AUTOSAR XML (schema 4-2-2)
package /STELLANTIS/EPT/ASWCs
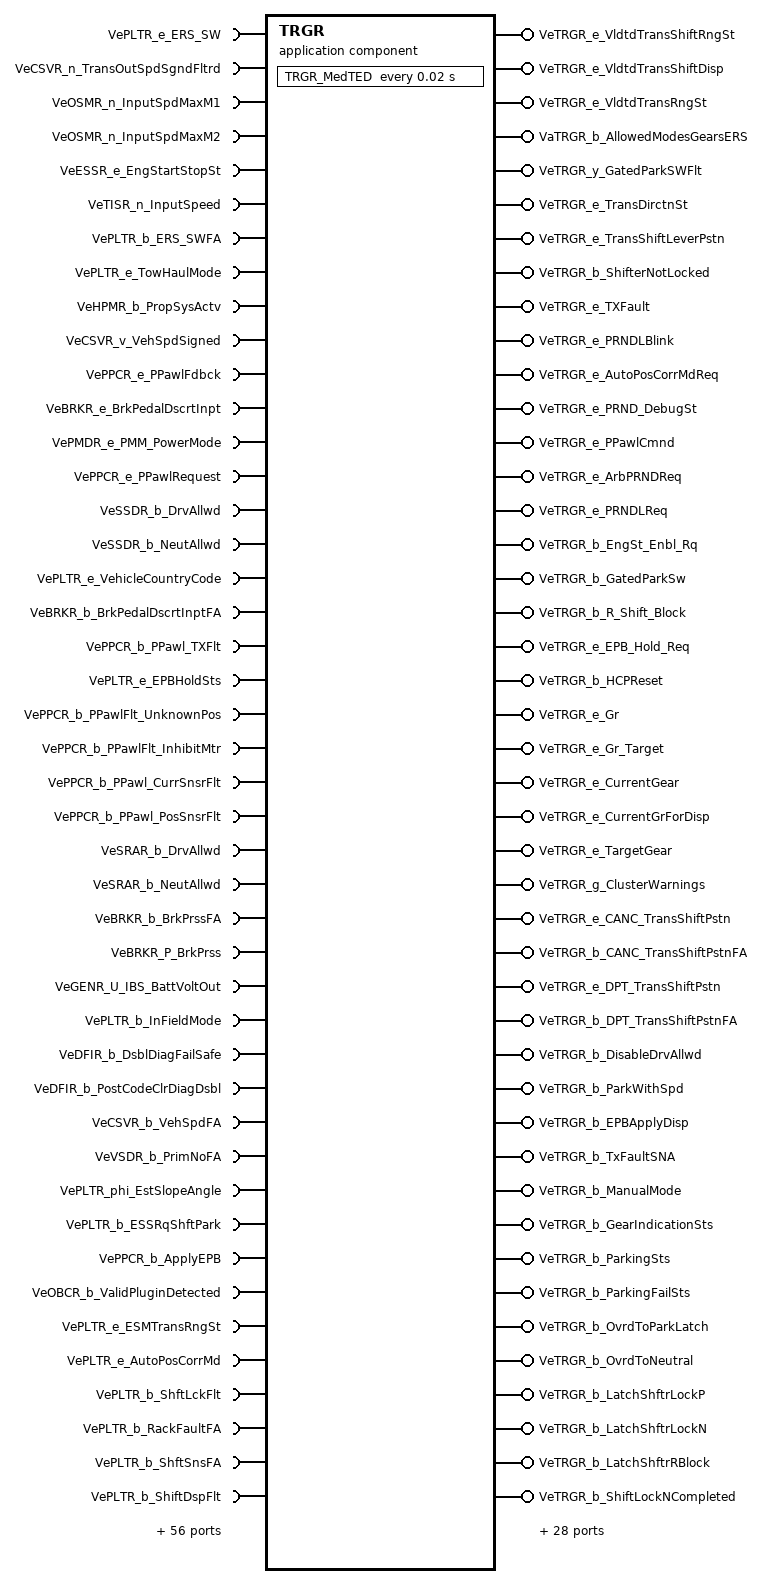
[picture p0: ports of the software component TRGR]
  application sw component type TRGR
    97 x require port:
      VePLTR_e_ERS_SW: variation-point={short-label=vpVePLTR_e_ERS_SW, sw-syscond=1}, nonqueued-receiver-com-spec{data-element=Value, init-value=CeTRGR_e_ERSBttn_NotActvtd}, required-interface=VePLTR_e_ERS_SW
      VeCSVR_n_TransOutSpdSgndFltrd: nonqueued-receiver-com-spec{data-element=Value, init-value=0}, required-interface=VeCSVR_n_TransOutSpdSgndFltrd
      VeOSMR_n_InputSpdMaxM1: variation-point={short-label=vpVeOSMR_n_InputSpdMaxM1, sw-syscond=1}, nonqueued-receiver-com-spec{data-element=Value, init-value=0}, required-interface=VeOSMR_n_InputSpdMaxM1
      VeOSMR_n_InputSpdMaxM2: variation-point={short-label=vpVeOSMR_n_InputSpdMaxM2, sw-syscond=1}, nonqueued-receiver-com-spec{data-element=Value, init-value=0}, required-interface=VeOSMR_n_InputSpdMaxM2
      VeESSR_e_EngStartStopSt: variation-point={short-label=vpVeESSR_e_EngStartStopSt, sw-syscond=1}, nonqueued-receiver-com-spec{data-element=Value, init-value=CeESSR_e_EngOff}, required-interface=VeESSR_e_EngStartStopSt
      VeTISR_n_InputSpeed: variation-point={short-label=vpVeTISR_n_InputSpeed, sw-syscond=1}, nonqueued-receiver-com-spec{data-element=Value, init-value=0}, required-interface=VeTISR_n_InputSpeed
      VePLTR_b_ERS_SWFA: variation-point={short-label=vpVePLTR_b_ERS_SWFA, sw-syscond=1}, nonqueued-receiver-com-spec{data-element=Value, init-value=0}, required-interface=VePLTR_b_ERS_SWFA
      VePLTR_e_TowHaulMode: variation-point={short-label=vpVePLTR_e_TowHaulMode, sw-syscond=1}, nonqueued-receiver-com-spec{data-element=Value, init-value=CePLTR_e_Towing_MD_RQ_OFF}, required-interface=VePLTR_e_TowHaulMode
      VeHPMR_b_PropSysActv: variation-point={short-label=vpVeHPMR_b_PropSysActv, sw-syscond=1}, nonqueued-receiver-com-spec{data-element=Value, init-value=0}, required-interface=VeHPMR_b_PropSysActv
      VeCSVR_v_VehSpdSigned: nonqueued-receiver-com-spec{data-element=Value, init-value=0}, required-interface=VeCSVR_v_VehSpdSigned
      VePPCR_e_PPawlFdbck: variation-point={short-label=vpVePPCR_e_PPawlFdbck, sw-syscond=1}, nonqueued-receiver-com-spec{data-element=Value, init-value=CePPCR_e_PPAWL_UNKNOWN_Position}, required-interface=VePPCR_e_PPawlFdbck
      VeBRKR_e_BrkPedalDscrtInpt: nonqueued-receiver-com-spec{data-element=Value, init-value=CeBRKR_e_BrkNotApplied}, required-interface=VeBRKR_e_BrkPedalDscrtInpt
      VePMDR_e_PMM_PowerMode: variation-point={short-label=vpVePMDR_e_PMM_PowerMode, sw-syscond=1}, nonqueued-receiver-com-spec{data-element=Value, init-value=CePMDR_e_PowerMode_Off}, required-interface=VePMDR_e_PMM_PowerMode
      VePPCR_e_PPawlRequest: variation-point={short-label=vpVePPCR_e_PPawlRequest, sw-syscond=1}, nonqueued-receiver-com-spec{data-element=Value, init-value=CePPCR_e_PPAWL_UNKNOWN_Request}, required-interface=VePPCR_e_PPawlRequest
      VeSSDR_b_DrvAllwd: nonqueued-receiver-com-spec{data-element=Value, init-value=0}, required-interface=VeSSDR_b_DrvAllwd
      VeSSDR_b_NeutAllwd: nonqueued-receiver-com-spec{data-element=Value, init-value=0}, required-interface=VeSSDR_b_NeutAllwd
      VePLTR_e_VehicleCountryCode: variation-point={short-label=vpVePLTR_e_VehicleCountryCode, sw-syscond=1}, nonqueued-receiver-com-spec{data-element=Value, init-value=CePLTR_e_VCC_OTHERS}, required-interface=VePLTR_e_VehicleCountryCode
      VeBRKR_b_BrkPedalDscrtInptFA: nonqueued-receiver-com-spec{data-element=Value, init-value=0}, required-interface=VeBRKR_b_BrkPedalDscrtInptFA
      VePPCR_b_PPawl_TXFlt: variation-point={short-label=vpVePPCR_b_PPawl_TXFlt, sw-syscond=1}, nonqueued-receiver-com-spec{data-element=Value, init-value=0}, required-interface=VePPCR_b_PPawl_TXFlt
      VePLTR_e_EPBHoldSts: nonqueued-receiver-com-spec{data-element=Value, init-value=CePLTR_e_EPBHoldSts_REL}, required-interface=VePLTR_e_EPBHoldSts
      VePPCR_b_PPawlFlt_UnknownPos: variation-point={short-label=vpVePPCR_b_PPawlFlt_UnknownPos, sw-syscond=1}, nonqueued-receiver-com-spec{data-element=Value, init-value=0}, required-interface=VePPCR_b_PPawlFlt_UnknownPos
      VePPCR_b_PPawlFlt_InhibitMtr: variation-point={short-label=vpVePPCR_b_PPawlFlt_InhibitMtr, sw-syscond=1}, nonqueued-receiver-com-spec{data-element=Value, init-value=0}, required-interface=VePPCR_b_PPawlFlt_InhibitMtr
      VePPCR_b_PPawl_CurrSnsrFlt: variation-point={short-label=vpVePPCR_b_PPawl_CurrSnsrFlt, sw-syscond=1}, nonqueued-receiver-com-spec{data-element=Value, init-value=0}, required-interface=VePPCR_b_PPawl_CurrSnsrFlt
      VePPCR_b_PPawl_PosSnsrFlt: variation-point={short-label=vpVePPCR_b_PPawl_PosSnsrFlt, sw-syscond=1}, nonqueued-receiver-com-spec{data-element=Value, init-value=0}, required-interface=VePPCR_b_PPawl_PosSnsrFlt
      VeSRAR_b_DrvAllwd: nonqueued-receiver-com-spec{data-element=Value, init-value=0}, required-interface=VeSRAR_b_DrvAllwd
      VeSRAR_b_NeutAllwd: nonqueued-receiver-com-spec{data-element=Value, init-value=0}, required-interface=VeSRAR_b_NeutAllwd
      VeBRKR_b_BrkPrssFA: nonqueued-receiver-com-spec{data-element=Value, init-value=0}, required-interface=VeBRKR_b_BrkPrssFA
      VeBRKR_P_BrkPrss: nonqueued-receiver-com-spec{data-element=Value, init-value=0}, required-interface=VeBRKR_P_BrkPrss
      VeGENR_U_IBS_BattVoltOut: variation-point={short-label=vpVeGENR_U_IBS_BattVoltOut, sw-syscond=1}, nonqueued-receiver-com-spec{data-element=Value, init-value=0}, required-interface=VeGENR_U_IBS_BattVoltOut
      VePLTR_b_InFieldMode: variation-point={short-label=vpVePLTR_b_InFieldMode, sw-syscond=1}, nonqueued-receiver-com-spec{data-element=Value, init-value=0}, required-interface=VePLTR_b_InFieldMode
      VeDFIR_b_DsblDiagFailSafe: variation-point={short-label=vpVeDFIR_b_DsblDiagFailSafe, sw-syscond=1}, nonqueued-receiver-com-spec{data-element=Value, init-value=0}, required-interface=VeDFIR_b_DsblDiagFailSafe
      VeDFIR_b_PostCodeClrDiagDsbl: variation-point={short-label=vpVeDFIR_b_PostCodeClrDiagDsbl, sw-syscond=1}, nonqueued-receiver-com-spec{data-element=Value, init-value=0}, required-interface=VeDFIR_b_PostCodeClrDiagDsbl
      VeCSVR_b_VehSpdFA: nonqueued-receiver-com-spec{data-element=Value, init-value=0}, required-interface=VeCSVR_b_VehSpdFA
      VeVSDR_b_PrimNoFA: nonqueued-receiver-com-spec{data-element=Value, init-value=0}, required-interface=VeVSDR_b_PrimNoFA
      VePLTR_phi_EstSlopeAngle: variation-point={short-label=vpVePLTR_phi_EstSlopeAngle, sw-syscond=1}, nonqueued-receiver-com-spec{data-element=Value, init-value=0}, required-interface=VePLTR_phi_EstSlopeAngle
      VePLTR_b_ESSRqShftPark: variation-point={short-label=vpVePLTR_b_ESSRqShftPark, sw-syscond=1}, nonqueued-receiver-com-spec{data-element=Value, init-value=0}, required-interface=VePLTR_b_ESSRqShftPark
      VePPCR_b_ApplyEPB: variation-point={short-label=vpVePPCR_b_ApplyEPB, sw-syscond=1}, nonqueued-receiver-com-spec{data-element=Value, init-value=0}, required-interface=VePPCR_b_ApplyEPB
      VeOBCR_b_ValidPluginDetected: nonqueued-receiver-com-spec{data-element=Value, init-value=0}, required-interface=VeOBCR_b_ValidPluginDetected
      VePLTR_e_ESMTransRngSt: variation-point={short-label=vpVePLTR_e_ESMTransRngSt, sw-syscond=1}, nonqueued-receiver-com-spec{data-element=Value, init-value=CeTRGR_e_NoSelectionAvailable}, required-interface=VePLTR_e_ESMTransRngSt
      VePLTR_e_AutoPosCorrMd: variation-point={short-label=vpVePLTR_e_AutoPosCorrMd, sw-syscond=1}, nonqueued-receiver-com-spec{data-element=Value, init-value=CeTRGR_e_AutoPosCorrMd_Off}, required-interface=VePLTR_e_AutoPosCorrMd
      VePLTR_b_ShftLckFlt: variation-point={short-label=vpVePLTR_b_ShftLckFlt, sw-syscond=1}, nonqueued-receiver-com-spec{data-element=Value, init-value=0}, required-interface=VePLTR_b_ShftLckFlt
      VePLTR_b_RackFaultFA: variation-point={short-label=vpVePLTR_b_RackFaultFA, sw-syscond=1}, nonqueued-receiver-com-spec{data-element=Value, init-value=0}, required-interface=VePLTR_b_RackFaultFA
      VePLTR_b_ShftSnsFA: variation-point={short-label=vpVePLTR_b_ShftSnsFA, sw-syscond=1}, nonqueued-receiver-com-spec{data-element=Value, init-value=0}, required-interface=VePLTR_b_ShftSnsFA
      VePLTR_b_ShiftDspFlt: variation-point={short-label=vpVePLTR_b_ShiftDspFlt, sw-syscond=1}, nonqueued-receiver-com-spec{data-element=Value, init-value=0}, required-interface=VePLTR_b_ShiftDspFlt
      VePLTR_e_Prmry_TransShiftPstn: variation-point={short-label=vpVePLTR_e_Prmry_TransShiftPstn, sw-syscond=1}, nonqueued-receiver-com-spec{data-element=Value, init-value=CeTRGR_e_NoSelectionAvailable}, required-interface=VePLTR_e_Prmry_TransShiftPstn
      VePLTR_b_Prmry_TransShiftPstnFA: variation-point={short-label=vpVePLTR_b_Prmry_TransShiftPstnFA, sw-syscond=1}, nonqueued-receiver-com-spec{data-element=Value, init-value=0}, required-interface=VePLTR_b_Prmry_TransShiftPstnFA
      VePLTR_e_Scndry_TransShiftPstn: variation-point={short-label=vpVePLTR_e_Scndry_TransShiftPstn, sw-syscond=1}, nonqueued-receiver-com-spec{data-element=Value, init-value=CeTRGR_e_NoSelectionAvailable}, required-interface=VePLTR_e_Scndry_TransShiftPstn
      VePLTR_b_Scndry_TransShiftPstnFA: variation-point={short-label=vpVePLTR_b_Scndry_TransShiftPstnFA, sw-syscond=1}, nonqueued-receiver-com-spec{data-element=Value, init-value=0}, required-interface=VePLTR_b_Scndry_TransShiftPstnFA
      VePLTR_y_GatedParkSwFlt: variation-point={short-label=vpVePLTR_y_GatedParkSwFlt, sw-syscond=1}, nonqueued-receiver-com-spec{data-element=Value, init-value=0}, required-interface=VePLTR_y_GatedParkSwFlt
      VePLTR_e_ShiftLeverPosReq: variation-point={short-label=vpVePLTR_e_ShiftLeverPosReq, sw-syscond=1}, nonqueued-receiver-com-spec{data-element=Value, init-value=CeTRGR_e_NoSelectionAvailable}, required-interface=VePLTR_e_ShiftLeverPosReq
      VePLTR_b_ShiftLeverFailSts: variation-point={short-label=vpVePLTR_b_ShiftLeverFailSts, sw-syscond=1}, nonqueued-receiver-com-spec{data-element=Value, init-value=0}, required-interface=VePLTR_b_ShiftLeverFailSts
      VePLTR_b_PRNDFailSts: variation-point={short-label=vpVePLTR_b_PRNDFailSts, sw-syscond=1}, nonqueued-receiver-com-spec{data-element=Value, init-value=0}, required-interface=VePLTR_b_PRNDFailSts
      VePLTR_b_RFHub_ForcePark: variation-point={short-label=vpVePLTR_b_RFHub_ForcePark, sw-syscond=1}, nonqueued-receiver-com-spec{data-element=Value, init-value=0}, required-interface=VePLTR_b_RFHub_ForcePark
      VePMDR_b_EngineOffRequest: variation-point={short-label=vpVePMDR_b_EngineOffRequest, sw-syscond=1}, nonqueued-receiver-com-spec{data-element=Value, init-value=0}, required-interface=VePMDR_b_EngineOffRequest
      VeTRIR_b_SCCActv: variation-point={short-label=vpVeTRIR_b_SCCActv, sw-syscond=1}, nonqueued-receiver-com-spec{data-element=Value, init-value=0}, required-interface=VeTRIR_b_SCCActv
      VePLTR_e_MRM_Status: variation-point={short-label=vpVePLTR_e_MRM_Status, sw-syscond=1}, nonqueued-receiver-com-spec{data-element=Value, init-value=CePLTR_e_Not_Active}, required-interface=VePLTR_e_MRM_Status
      VePLTR_b_MRM_Status_FA: variation-point={short-label=vpVePLTR_b_MRM_Status_FA, sw-syscond=1}, nonqueued-receiver-com-spec{data-element=Value, init-value=0}, required-interface=VePLTR_b_MRM_Status_FA
      VeSSDR_b_DrvAllwdTPChck: variation-point={short-label=vpVeSSDR_b_DrvAllwdTPChck, sw-syscond=1}, nonqueued-receiver-com-spec{data-element=Value, init-value=0}, required-interface=VeSSDR_b_DrvAllwdTPChck
      VeFCPR_b_FCPS_H2_RefuelSts: variation-point={short-label=vpVeFCPR_b_FCPS_H2_RefuelSts, sw-syscond=1}, nonqueued-receiver-com-spec{data-element=Value, init-value=0}, required-interface=VeFCPR_b_FCPS_H2_RefuelSts
      VePLTR_b_DAI_Enbl: variation-point={short-label=vpVePLTR_b_DAI_Enbl, sw-syscond=1}, nonqueued-receiver-com-spec{data-element=Value, init-value=0}, required-interface=VePLTR_b_DAI_Enbl
      VeDMAB_y_StatusByte_ParkNeutSwOut: variation-point={short-label=vpVeDMAB_y_StatusByte_ParkNeutSwOut, sw-syscond=1}, nonqueued-receiver-com-spec{data-element=Value, init-value=0}, required-interface=VeDMAB_y_StatusByte_ParkNeutSwOut
      VeDCAB_d_IP_PRNDLTestFlags_DidWrite: nonqueued-receiver-com-spec{data-element=Value, init-value=0}, required-interface=VeDCAB_d_IP_PRNDLTestFlags_DidWrite
      VePLTR_b_ImmoParkReq: variation-point={short-label=vpVePLTR_b_ImmoParkReq, sw-syscond=1}, nonqueued-receiver-com-spec{data-element=Value, init-value=0}, required-interface=VePLTR_b_ImmoParkReq
      VeINVR_e_MtrB_InvrtrSt: variation-point={short-label=vpVeINVR_e_MtrB_InvrtrSt, sw-syscond=1}, nonqueued-receiver-com-spec{data-element=Value, init-value=CeINVR_e_NormalPowerStageOff}, required-interface=VeINVR_e_MtrB_InvrtrSt
      VeINVR_e_MtrA_6SOEnbl: variation-point={short-label=vpVeINVR_e_MtrA_6SOEnbl, sw-syscond=1}, nonqueued-receiver-com-spec{data-element=Value, init-value=CeINVR_e_ThreePS}, required-interface=VeINVR_e_MtrA_6SOEnbl
      VeINVR_e_MtrA_InvrtrSt: variation-point={short-label=vpVeINVR_e_MtrA_InvrtrSt, sw-syscond=1}, nonqueued-receiver-com-spec{data-element=Value, init-value=CeINVR_e_NormalPowerStageOff}, required-interface=VeINVR_e_MtrA_InvrtrSt
      VeHPMR_b_CntrlrPwrHold: variation-point={short-label=vpVeHPMR_b_CntrlrPwrHold, sw-syscond=1}, nonqueued-receiver-com-spec{data-element=Value, init-value=0}, required-interface=VeHPMR_b_CntrlrPwrHold
      VeCCTR_b_CcAccelSts: variation-point={short-label=vpVeCCTR_b_CcAccelSts, sw-syscond=1}, nonqueued-receiver-com-spec{data-element=Value, init-value=0}, required-interface=VeCCTR_b_CcAccelSts
      VeCCTR_b_CcDecelSts: variation-point={short-label=vpVeCCTR_b_CcDecelSts, sw-syscond=1}, nonqueued-receiver-com-spec{data-element=Value, init-value=0}, required-interface=VeCCTR_b_CcDecelSts
      VeADAR_e_LeftActuationStatus: variation-point={short-label=vpVeADAR_e_LeftActuationStatus, sw-syscond=1}, nonqueued-receiver-com-spec{data-element=Value, init-value=CeADAR_e_SS_Indeterminate}, required-interface=VeADAR_e_LeftActuationStatus
      VeADAR_e_RightActuationStatus: variation-point={short-label=vpVeADAR_e_RightActuationStatus, sw-syscond=1}, nonqueued-receiver-com-spec{data-element=Value, init-value=CeADAR_e_SS_Indeterminate}, required-interface=VeADAR_e_RightActuationStatus
      VeADIR_b_LftWEDClosingFail: variation-point={short-label=vpVeADIR_b_LftWEDClosingFail, sw-syscond=1}, nonqueued-receiver-com-spec{data-element=Value, init-value=0}, required-interface=VeADIR_b_LftWEDClosingFail
      VeADIR_b_RtWEDClosingFail: variation-point={short-label=vpVeADIR_b_RtWEDClosingFail, sw-syscond=1}, nonqueued-receiver-com-spec{data-element=Value, init-value=0}, required-interface=VeADIR_b_RtWEDClosingFail
      VeADIR_e_WEDMechFailure_Sts: variation-point={short-label=vpVeADIR_e_WEDMechFailure_Sts, sw-syscond=1}, nonqueued-receiver-com-spec{data-element=Value, init-value=CeADIR_e_BreakageNotTested}, required-interface=VeADIR_e_WEDMechFailure_Sts
      VeDMAB_y_StatusByte_LF_WHL_HubDisConActCntrl: variation-point={short-label=vpVeDMAB_y_StatusByte_LF_WHL_HubDisConActCntrl, sw-syscond=1}, nonqueued-receiver-com-spec{data-element=Value, init-value=0}, required-interface=VeDMAB_y_StatusByte_LF_WHL_HubDisConActCntrl
      VeDMAB_y_StatusByte_LF_WHL_HubDisConActPosSnsr: variation-point={short-label=vpVeDMAB_y_StatusByte_LF_WHL_HubDisConActPosSnsr, sw-syscond=1}, nonqueued-receiver-com-spec{data-element=Value, init-value=0}, required-interface=VeDMAB_y_StatusByte_LF_WHL_HubDisConActPosSnsr
      VeDMAB_y_StatusByte_LF_WHL_HubDisConActPosSnsrCktPerf: variation-point={short-label=vpVeDMAB_y_StatusByte_LF_WHL_HubDisConActPosSnsrCktPerf, sw-syscond=1}, nonqueued-receiver-com-spec{data-element=Value, init-value=0}, required-interface=VeDMAB_y_StatusByte_LF_WHL_HubDisConActPosSnsrCktPerf
      VeDMAB_y_StatusByte_RF_WHL_HubDisConActCntrl: variation-point={short-label=vpVeDMAB_y_StatusByte_RF_WHL_HubDisConActCntrl, sw-syscond=1}, nonqueued-receiver-com-spec{data-element=Value, init-value=0}, required-interface=VeDMAB_y_StatusByte_RF_WHL_HubDisConActCntrl
      VeDMAB_y_StatusByte_RF_WHL_HubDisConActPosSnsr: variation-point={short-label=vpVeDMAB_y_StatusByte_RF_WHL_HubDisConActPosSnsr, sw-syscond=1}, nonqueued-receiver-com-spec{data-element=Value, init-value=0}, required-interface=VeDMAB_y_StatusByte_RF_WHL_HubDisConActPosSnsr
      VeDMAB_y_StatusByte_RF_WHL_HubDisConActPosSnsrCktPerf: variation-point={short-label=vpVeDMAB_y_StatusByte_RF_WHL_HubDisConActPosSnsrCktPerf, sw-syscond=1}, nonqueued-receiver-com-spec{data-element=Value, init-value=0}, required-interface=VeDMAB_y_StatusByte_RF_WHL_HubDisConActPosSnsrCktPerf
      VePLTR_e_SelectSpdSts: variation-point={short-label=vpVePLTR_e_SelectSpdSts, sw-syscond=1}, nonqueued-receiver-com-spec{data-element=Value, init-value=CePLTR_e_SelectSpdSts_OFF}, required-interface=VePLTR_e_SelectSpdSts
      VePLTR_b_SelectSpdSts_FA: variation-point={short-label=vpVePLTR_b_SelectSpdSts_FA, sw-syscond=1}, nonqueued-receiver-com-spec{data-element=Value, init-value=0}, required-interface=VePLTR_b_SelectSpdSts_FA
      VePLTR_e_ParkingGearShiftReq_BSM: variation-point={short-label=vpVePLTR_e_ParkingGearShiftReq_BSM, sw-syscond=1}, nonqueued-receiver-com-spec{data-element=Value, init-value=CePLTR_e_GearShiftReq_Idle}, required-interface=VePLTR_e_ParkingGearShiftReq_BSM
      VePLTR_b_ParkingGearShiftReq_BSM_FA: variation-point={short-label=vpVePLTR_b_ParkingGearShiftReq_BSM_FA, sw-syscond=1}, nonqueued-receiver-com-spec{data-element=Value, init-value=0}, required-interface=VePLTR_b_ParkingGearShiftReq_BSM_FA
      VeHSWR_b_HoodOpen: variation-point={short-label=vpVeHSWR_b_HoodOpen, sw-syscond=1}, nonqueued-receiver-com-spec{data-element=Value, init-value=0}, required-interface=VeHSWR_b_HoodOpen
      VeDMIR_e_BrakingMdReq: variation-point={short-label=vpVeDMIR_e_BrakingMdReq, sw-syscond=1}, nonqueued-receiver-com-spec{data-element=Value, init-value=CeDMIR_e_BtnNotPrsd}, required-interface=VeDMIR_e_BrakingMdReq
      VeFWDR_e_Tcase_Stat: variation-point={short-label=vpVeFWDR_e_Tcase_Stat, sw-syscond=1}, nonqueued-receiver-com-spec{data-element=Value, init-value=CeFWDR_e_ShiftINProg}, required-interface=VeFWDR_e_Tcase_Stat
      VePLTR_b_Secure_Idle_Req: variation-point={short-label=vpVePLTR_b_Secure_Idle_Req, sw-syscond=1}, nonqueued-receiver-com-spec{data-element=Value, init-value=0}, required-interface=VePLTR_b_Secure_Idle_Req
      VePLTR_b_Secure_Idle_Req_FA: variation-point={short-label=vpVePLTR_b_Secure_Idle_Req_FA, sw-syscond=1}, nonqueued-receiver-com-spec{data-element=Value, init-value=0}, required-interface=VePLTR_b_Secure_Idle_Req_FA
      VePLTR_y_FobSearchResult: variation-point={short-label=vpVePLTR_y_FobSearchResult, sw-syscond=1}, nonqueued-receiver-com-spec{data-element=Value, init-value=0}, required-interface=VePLTR_y_FobSearchResult
      VePLTR_b_FobSearchResult_FA: variation-point={short-label=vpVePLTR_b_FobSearchResult_FA, sw-syscond=1}, nonqueued-receiver-com-spec{data-element=Value, init-value=0}, required-interface=VePLTR_b_FobSearchResult_FA
      VeVTLR_e_DschrgSysSts: variation-point={short-label=vpVeVTLR_e_DschrgSysSts, sw-syscond=1}, nonqueued-receiver-com-spec{data-element=Value, init-value=CeVTLR_e_DschrgInactv}, required-interface=VeVTLR_e_DschrgSysSts
      VeRTMR_e_WEDLearningProcedure: variation-point={short-label=vpVeRTMR_e_WEDLearningProcedure, sw-syscond=1}, nonqueued-receiver-com-spec{data-element=Value, init-value=CeRTMR_e_WED_Not_Active}, required-interface=VeRTMR_e_WEDLearningProcedure
      VePLTR_b_ProxiCADM: variation-point={short-label=vpVePLTR_b_ProxiCADM, sw-syscond=1}, nonqueued-receiver-com-spec{data-element=Value, init-value=0}, required-interface=VePLTR_b_ProxiCADM
      VePLTR_b_ProxiCADM2: variation-point={short-label=vpVePLTR_b_ProxiCADM2, sw-syscond=1}, nonqueued-receiver-com-spec{data-element=Value, init-value=0}, required-interface=VePLTR_b_ProxiCADM2
      VePLTR_e_MRM_Status_C2: variation-point={short-label=vpVePLTR_e_MRM_Status_C2, sw-syscond=1}, nonqueued-receiver-com-spec{data-element=Value, init-value=CePLTR_e_Not_Active}, required-interface=VePLTR_e_MRM_Status_C2
      VePLTR_e_MRM_Status_C2_FA: variation-point={short-label=vpVePLTR_e_MRM_Status_C2_FA, sw-syscond=1}, nonqueued-receiver-com-spec{data-element=Value, init-value=0}, required-interface=VePLTR_e_MRM_Status_C2_FA
    69 x provide port:
      VeTRGR_e_VldtdTransShiftRngSt: nonqueued-sender-com-spec{data-element=Value, init-value=CeTRGR_e_NoSelectionAvailable}, provided-interface=VeTRGR_e_VldtdTransShiftRngSt
      VeTRGR_e_VldtdTransShiftDisp: nonqueued-sender-com-spec{data-element=Value, init-value=0}, provided-interface=VeTRGR_e_VldtdTransShiftDisp
      VeTRGR_e_VldtdTransRngSt: nonqueued-sender-com-spec{data-element=Value, init-value=CeTRGR_e_NoSelectionAvailable}, provided-interface=VeTRGR_e_VldtdTransRngSt
      VaTRGR_b_AllowedModesGearsERS: nonqueued-sender-com-spec{data-element=Value, init-value=7 x 0}, provided-interface=VaTRGR_b_AllowedModesGearsERS
      VeTRGR_y_GatedParkSWFlt: nonqueued-sender-com-spec{data-element=Value, init-value=0}, provided-interface=VeTRGR_y_GatedParkSWFlt
      VeTRGR_e_TransDirctnSt: nonqueued-sender-com-spec{data-element=Value, init-value=CeTRGR_e_NoSelectionAvailable}, provided-interface=VeTRGR_e_TransDirctnSt
      VeTRGR_e_TransShiftLeverPstn: nonqueued-sender-com-spec{data-element=Value, init-value=0}, provided-interface=VeTRGR_e_TransShiftLeverPstn
      VeTRGR_b_ShifterNotLocked: nonqueued-sender-com-spec{data-element=Value, init-value=0}, provided-interface=VeTRGR_b_ShifterNotLocked
      VeTRGR_e_TXFault: nonqueued-sender-com-spec{data-element=Value, init-value=CeTRGR_e_TXFlt_OK}, provided-interface=VeTRGR_e_TXFault
      VeTRGR_e_PRNDLBlink: nonqueued-sender-com-spec{data-element=Value, init-value=CeTRGR_e_PRNDBlinkNone}, provided-interface=VeTRGR_e_PRNDLBlink
      VeTRGR_e_AutoPosCorrMdReq: nonqueued-sender-com-spec{data-element=Value, init-value=CeTRGR_e_AutoPosCorrMd_Off}, provided-interface=VeTRGR_e_AutoPosCorrMdReq
      VeTRGR_e_PRND_DebugSt: nonqueued-sender-com-spec{data-element=Value, init-value=CeTRGR_e_PRNDDbgSt1}, provided-interface=VeTRGR_e_PRND_DebugSt
      VeTRGR_e_PPawlCmnd: nonqueued-sender-com-spec{data-element=Value, init-value=CeTRGR_e_PPawlIdle}, provided-interface=VeTRGR_e_PPawlCmnd
      VeTRGR_e_ArbPRNDReq: nonqueued-sender-com-spec{data-element=Value, init-value=CeTRGR_e_NoSelectionAvailable}, provided-interface=VeTRGR_e_ArbPRNDReq
      VeTRGR_e_PRNDLReq: nonqueued-sender-com-spec{data-element=Value, init-value=0}, provided-interface=VeTRGR_e_PRNDLReq
      VeTRGR_b_EngSt_Enbl_Rq: nonqueued-sender-com-spec{data-element=Value, init-value=0}, provided-interface=VeTRGR_b_EngSt_Enbl_Rq
      VeTRGR_b_GatedParkSw: nonqueued-sender-com-spec{data-element=Value, init-value=0}, provided-interface=VeTRGR_b_GatedParkSw
      VeTRGR_b_R_Shift_Block: nonqueued-sender-com-spec{data-element=Value, init-value=0}, provided-interface=VeTRGR_b_R_Shift_Block
      VeTRGR_e_EPB_Hold_Req: nonqueued-sender-com-spec{data-element=Value, init-value=CeTRGR_e_EPBReq_NA}, provided-interface=VeTRGR_e_EPB_Hold_Req
      VeTRGR_b_HCPReset: nonqueued-sender-com-spec{data-element=Value, init-value=0}, provided-interface=VeTRGR_b_HCPReset
      VeTRGR_e_Gr: nonqueued-sender-com-spec{data-element=Value, init-value=0}, provided-interface=VeTRGR_e_Gr
      VeTRGR_e_Gr_Target: nonqueued-sender-com-spec{data-element=Value, init-value=0}, provided-interface=VeTRGR_e_Gr_Target
      VeTRGR_e_CurrentGear: nonqueued-sender-com-spec{data-element=Value, init-value=0}, provided-interface=VeTRGR_e_CurrentGear
      VeTRGR_e_CurrentGrForDisp: nonqueued-sender-com-spec{data-element=Value, init-value=0}, provided-interface=VeTRGR_e_CurrentGrForDisp
      VeTRGR_e_TargetGear: nonqueued-sender-com-spec{data-element=Value, init-value=0}, provided-interface=VeTRGR_e_TargetGear
      VeTRGR_g_ClusterWarnings: nonqueued-sender-com-spec{data-element=Value, init-value=0}, provided-interface=VeTRGR_g_ClusterWarnings
      VeTRGR_e_CANC_TransShiftPstn: nonqueued-sender-com-spec{data-element=Value, init-value=CeTRGR_e_NoSelectionAvailable}, provided-interface=VeTRGR_e_CANC_TransShiftPstn
      VeTRGR_b_CANC_TransShiftPstnFA: nonqueued-sender-com-spec{data-element=Value, init-value=0}, provided-interface=VeTRGR_b_CANC_TransShiftPstnFA
      VeTRGR_e_DPT_TransShiftPstn: nonqueued-sender-com-spec{data-element=Value, init-value=CeTRGR_e_NoSelectionAvailable}, provided-interface=VeTRGR_e_DPT_TransShiftPstn
      VeTRGR_b_DPT_TransShiftPstnFA: nonqueued-sender-com-spec{data-element=Value, init-value=0}, provided-interface=VeTRGR_b_DPT_TransShiftPstnFA
      VeTRGR_b_DisableDrvAllwd: nonqueued-sender-com-spec{data-element=Value, init-value=0}, provided-interface=VeTRGR_b_DisableDrvAllwd
      VeTRGR_b_ParkWithSpd: nonqueued-sender-com-spec{data-element=Value, init-value=0}, provided-interface=VeTRGR_b_ParkWithSpd
      VeTRGR_b_EPBApplyDisp: nonqueued-sender-com-spec{data-element=Value, init-value=0}, provided-interface=VeTRGR_b_EPBApplyDisp
      VeTRGR_b_TxFaultSNA: nonqueued-sender-com-spec{data-element=Value, init-value=0}, provided-interface=VeTRGR_b_TxFaultSNA
      VeTRGR_b_ManualMode: nonqueued-sender-com-spec{data-element=Value, init-value=0}, provided-interface=VeTRGR_b_ManualMode
      VeTRGR_b_GearIndicationSts: nonqueued-sender-com-spec{data-element=Value, init-value=0}, provided-interface=VeTRGR_b_GearIndicationSts
      VeTRGR_b_ParkingSts: nonqueued-sender-com-spec{data-element=Value, init-value=0}, provided-interface=VeTRGR_b_ParkingSts
      VeTRGR_b_ParkingFailSts: nonqueued-sender-com-spec{data-element=Value, init-value=0}, provided-interface=VeTRGR_b_ParkingFailSts
      VeTRGR_b_OvrdToParkLatch: nonqueued-sender-com-spec{data-element=Value, init-value=0}, provided-interface=VeTRGR_b_OvrdToParkLatch
      VeTRGR_b_OvrdToNeutral: nonqueued-sender-com-spec{data-element=Value, init-value=0}, provided-interface=VeTRGR_b_OvrdToNeutral
      VeTRGR_b_LatchShftrLockP: nonqueued-sender-com-spec{data-element=Value, init-value=0}, provided-interface=VeTRGR_b_LatchShftrLockP
      VeTRGR_b_LatchShftrLockN: nonqueued-sender-com-spec{data-element=Value, init-value=0}, provided-interface=VeTRGR_b_LatchShftrLockN
      VeTRGR_b_LatchShftrRBlock: nonqueued-sender-com-spec{data-element=Value, init-value=0}, provided-interface=VeTRGR_b_LatchShftrRBlock
      VeTRGR_b_ShiftLockNCompleted: nonqueued-sender-com-spec{data-element=Value, init-value=0}, provided-interface=VeTRGR_b_ShiftLockNCompleted
      VeTRGR_e_ReverseSts: nonqueued-sender-com-spec{data-element=Value, init-value=CeTRGR_e_ReverseSts_Not_Inserted}, provided-interface=VeTRGR_e_ReverseSts
      VeTRGR_b_Secured_To_Shtdwn: nonqueued-sender-com-spec{data-element=Value, init-value=0}, provided-interface=VeTRGR_b_Secured_To_Shtdwn
      VeTRGR_b_UnexpRst: nonqueued-sender-com-spec{data-element=Value, init-value=0}, provided-interface=VeTRGR_b_UnexpRst
      VeTRGR_b_Reject_D: nonqueued-sender-com-spec{data-element=Value, init-value=0}, provided-interface=VeTRGR_b_Reject_D
      VeTRGR_b_Reject_R: nonqueued-sender-com-spec{data-element=Value, init-value=0}, provided-interface=VeTRGR_b_Reject_R
      VeTRGR_e_ESMTransRngSt: nonqueued-sender-com-spec{data-element=Value, init-value=CeTRGR_e_NoSelectionAvailable}, provided-interface=VeTRGR_e_ESMTransRngSt
      VeTRGR_b_ShifterLocked: nonqueued-sender-com-spec{data-element=Value, init-value=0}, provided-interface=VeTRGR_b_ShifterLocked
      VeTRGR_b_TransmissionFailSts: nonqueued-sender-com-spec{data-element=Value, init-value=0}, provided-interface=VeTRGR_b_TransmissionFailSts
      VeTRGR_b_CrankEnabled: nonqueued-sender-com-spec{data-element=Value, init-value=0}, provided-interface=VeTRGR_b_CrankEnabled
      VeTRGR_b_BrkApplied: nonqueued-sender-com-spec{data-element=Value, init-value=0}, provided-interface=VeTRGR_b_BrkApplied
      VeTRGR_b_BrakeFA: nonqueued-sender-com-spec{data-element=Value, init-value=0}, provided-interface=VeTRGR_b_BrakeFA
      VeTRGR_b_AutoPark_DAI: nonqueued-sender-com-spec{data-element=Value, init-value=0}, provided-interface=VeTRGR_b_AutoPark_DAI
      VeTRGR_d_IP_PRNDLTestFlags: variation-point={short-label=vpVeTRGR_d_IP_PRNDLTestFlags, sw-syscond=1}, nonqueued-sender-com-spec{data-element=Value, init-value=0}, provided-interface=VeTRGR_d_IP_PRNDLTestFlags
      VeTRGR_y_PRNDLTestFailStatus: variation-point={short-label=vpVeTRGR_y_PRNDLTestFailStatus, sw-syscond=1}, nonqueued-sender-com-spec{data-element=Value, init-value=0}, provided-interface=VeTRGR_y_PRNDLTestFailStatus
      VeTRGR_b_ADAS_Allowed: nonqueued-sender-com-spec{data-element=Value, init-value=0}, provided-interface=VeTRGR_b_ADAS_Allowed
      VeTRGR_b_ReadyToPark: nonqueued-sender-com-spec{data-element=Value, init-value=0}, provided-interface=VeTRGR_b_ReadyToPark
      VeTRGR_b_TransDirctnStFA: nonqueued-sender-com-spec{data-element=Value, init-value=0}, provided-interface=VeTRGR_b_TransDirctnStFA
      VeTRGR_e_TransShiftPstn: nonqueued-sender-com-spec{data-element=Value, init-value=CeTRGR_e_NoSelectionAvailable}, provided-interface=VeTRGR_e_TransShiftPstn
      VeTRGR_b_Force_Park_Neutral: nonqueued-sender-com-spec{data-element=Value, init-value=0}, provided-interface=VeTRGR_b_Force_Park_Neutral
      VeTRGR_e_HCP_Honored_Pstn: nonqueued-sender-com-spec{data-element=Value, init-value=CeTRGR_e_NoSelectionAvailable}, provided-interface=VeTRGR_e_HCP_Honored_Pstn
      VeTRGR_e_ShftRngSt_AEMD: nonqueued-sender-com-spec{data-element=Value, init-value=0}, provided-interface=VeTRGR_e_ShftRngSt_AEMD
      VeTRGR_e_Braking_Mode_Sts: nonqueued-sender-com-spec{data-element=Value, init-value=CeTRGR_e_BrakingMode_Not_Active}, provided-interface=VeTRGR_e_Braking_Mode_Sts
      VeTRGR_e_Braking_Mode_Indication_Sts: nonqueued-sender-com-spec{data-element=Value, init-value=CeTRGR_e_IndSts_OFF}, provided-interface=VeTRGR_e_Braking_Mode_Indication_Sts
      VeTRGR_e_SecureIdleSts: nonqueued-sender-com-spec{data-element=Value, init-value=0}, provided-interface=VeTRGR_e_SecureIdleSts
      VeTRGR_e_SecureIdle_HMI: nonqueued-sender-com-spec{data-element=Value, init-value=CeTRGR_e_SecureIdleHMI_Default}, provided-interface=VeTRGR_e_SecureIdle_HMI
    require port BeTRGR_d_IP_PRNDLTestFlags_Rx: variation-point={short-label=vpBeTRGR_d_IP_PRNDLTestFlags_Rx, sw-syscond=1}, nv-require-com-spec{init-value=0, variable=BeTRGR_d_IP_PRNDLTestFlags}, required-interface=BeTRGR_d_IP_PRNDLTestFlags
    require port NeTRGR_y_IP_PRNDLTestFailStatus_Rx: variation-point={short-label=vpNeTRGR_y_IP_PRNDLTestFailStatus_Rx, sw-syscond=1}, nv-require-com-spec{init-value=0, variable=NeTRGR_y_IP_PRNDLTestFailStatus}, required-interface=NeTRGR_y_IP_PRNDLTestFailStatus
    require port AeTRGR_y_PwrDwnSts_Rx: variation-point={short-label=vpAeTRGR_y_PwrDwnSts_Rx, sw-syscond=1}, nv-require-com-spec{init-value=0, variable=AeTRGR_y_PwrDwnSts}, required-interface=AeTRGR_y_PwrDwnSts
    provide port BeTRGR_d_IP_PRNDLTestFlags: variation-point={short-label=vpBeTRGR_d_IP_PRNDLTestFlags, sw-syscond=1}, nv-provide-com-spec{ram-block-init-value=0, variable=BeTRGR_d_IP_PRNDLTestFlags}, provided-interface=BeTRGR_d_IP_PRNDLTestFlags
    provide port NeTRGR_y_IP_PRNDLTestFailStatus: variation-point={short-label=vpNeTRGR_y_IP_PRNDLTestFailStatus, sw-syscond=1}, nv-provide-com-spec{ram-block-init-value=0, variable=NeTRGR_y_IP_PRNDLTestFailStatus}, provided-interface=NeTRGR_y_IP_PRNDLTestFailStatus
    provide port AeTRGR_y_PwrDwnSts: variation-point={short-label=vpAeTRGR_y_PwrDwnSts, sw-syscond=1}, nv-provide-com-spec{ram-block-init-value=0, variable=AeTRGR_y_PwrDwnSts}, provided-interface=AeTRGR_y_PwrDwnSts
    behavior IB_TRGR: data-type-mapping=msADTtoIDTMapping, handle-termination-and-restart=NO-SUPPORT
      timing event Event_MedTED: start-on-event=TRGR_MedTED, period=0.02
      init event Event_TRGR_ac_Init: start-on-event=TRGR_ac_Init
      init event Event_PwrOn: start-on-event=TRGR_PwrOn
      init event Event_PwrOff: start-on-event=TRGR_PwrOff
      data received event Event_DIDWrite_RWD2800_IPEEPRNDLTstFlg: start-on-event=DIDWrite_RWD2800_IPEEPRNDLTstFlg, data=VeDCAB_d_IP_PRNDLTestFlags_DidWrite.Value
      5 x runnable:
        TRGR_ac_Init
          data-send-points:
            22 x access:
              OUT_VeTRGR_e_SecureIdleSts_Value: accessed-variable=VeTRGR_e_SecureIdleSts.Value
              OUT_VeTRGR_e_SecureIdle_HMI_Value: accessed-variable=VeTRGR_e_SecureIdle_HMI.Value
              OUT_VaTRGR_b_AllowedModesGearsERS_Value: accessed-variable=VaTRGR_b_AllowedModesGearsERS.Value
              OUT_VeTRGR_e_VldtdTransShiftRngSt_Value: accessed-variable=VeTRGR_e_VldtdTransShiftRngSt.Value
              OUT_VeTRGR_e_VldtdTransRngSt_Value: accessed-variable=VeTRGR_e_VldtdTransRngSt.Value
              OUT_VeTRGR_e_TransDirctnSt_Value: accessed-variable=VeTRGR_e_TransDirctnSt.Value
              OUT_VeTRGR_e_TXFault_Value: accessed-variable=VeTRGR_e_TXFault.Value
              OUT_VeTRGR_e_PRNDLBlink_Value: accessed-variable=VeTRGR_e_PRNDLBlink.Value
              OUT_VeTRGR_e_AutoPosCorrMdReq_Value: accessed-variable=VeTRGR_e_AutoPosCorrMdReq.Value
              OUT_VeTRGR_e_PRND_DebugSt_Value: accessed-variable=VeTRGR_e_PRND_DebugSt.Value
              OUT_VeTRGR_e_PPawlCmnd_Value: accessed-variable=VeTRGR_e_PPawlCmnd.Value
              OUT_VeTRGR_e_ArbPRNDReq_Value: accessed-variable=VeTRGR_e_ArbPRNDReq.Value
              OUT_VeTRGR_e_EPB_Hold_Req_Value: accessed-variable=VeTRGR_e_EPB_Hold_Req.Value
              OUT_VeTRGR_e_CANC_TransShiftPstn_Value: accessed-variable=VeTRGR_e_CANC_TransShiftPstn.Value
              OUT_VeTRGR_e_DPT_TransShiftPstn_Value: accessed-variable=VeTRGR_e_DPT_TransShiftPstn.Value
              OUT_VeTRGR_e_ReverseSts_Value: accessed-variable=VeTRGR_e_ReverseSts.Value
              OUT_VeTRGR_e_ESMTransRngSt_Value: accessed-variable=VeTRGR_e_ESMTransRngSt.Value
              OUT_VeTRGR_e_TransShiftPstn_Value: accessed-variable=VeTRGR_e_TransShiftPstn.Value
              OUT_VeTRGR_e_HCP_Honored_Pstn_Value: accessed-variable=VeTRGR_e_HCP_Honored_Pstn.Value
              OUT_VeTRGR_e_Braking_Mode_Sts_Value: accessed-variable=VeTRGR_e_Braking_Mode_Sts.Value
              OUT_VeTRGR_e_Braking_Mode_Indication_Sts_Value: accessed-variable=VeTRGR_e_Braking_Mode_Indication_Sts.Value
              OUT_AeTRGR_y_PwrDwnSts_AeTRGR_y_PwrDwnSts: accessed-variable=AeTRGR_y_PwrDwnSts.AeTRGR_y_PwrDwnSts, variation-point={short-label=vpOUT_AeTRGR_y_PwrDwnSts_AeTRGR_y_PwrDwnSts, sw-syscond=1}
        TRGR_PwrOn
          data-receive-point-by-arguments:
            access IN_AeTRGR_y_PwrDwnSts_Rx_AeTRGR_y_PwrDwnSts: accessed-variable=AeTRGR_y_PwrDwnSts_Rx.AeTRGR_y_PwrDwnSts, variation-point={short-label=vpIN_AeTRGR_y_PwrDwnSts_Rx_AeTRGR_y_PwrDwnSts, sw-syscond=1}
            access IN_BeTRGR_d_IP_PRNDLTestFlags_Rx_BeTRGR_d_IP_PRNDLTestFlags: accessed-variable=BeTRGR_d_IP_PRNDLTestFlags_Rx.BeTRGR_d_IP_PRNDLTestFlags, variation-point={short-label=vpIN_BeTRGR_d_IP_PRNDLTestFlags_Rx_BeTRGR_d_IP_PRNDLTestFlags, sw-syscond=1}
            access IN_NeTRGR_y_IP_PRNDLTestFailStatus_Rx_NeTRGR_y_IP_PRNDLTestFailStatus: accessed-variable=NeTRGR_y_IP_PRNDLTestFailStatus_Rx.NeTRGR_y_IP_PRNDLTestFailStatus, variation-point={short-label=vpIN_NeTRGR_y_IP_PRNDLTestFailStatus_Rx_NeTRGR_y_IP_PRNDLTestFailStatus, sw-syscond=1}
          data-send-points:
            69 x access:
              OUT_VeTRGR_e_VldtdTransRngSt_Value: accessed-variable=VeTRGR_e_VldtdTransRngSt.Value
              OUT_VeTRGR_b_ManualMode_Value: accessed-variable=VeTRGR_b_ManualMode.Value
              OUT_VeTRGR_e_VldtdTransShiftRngSt_Value: accessed-variable=VeTRGR_e_VldtdTransShiftRngSt.Value
              OUT_VeTRGR_e_VldtdTransShiftDisp_Value: accessed-variable=VeTRGR_e_VldtdTransShiftDisp.Value
              OUT_VaTRGR_b_AllowedModesGearsERS_Value: accessed-variable=VaTRGR_b_AllowedModesGearsERS.Value
              OUT_VeTRGR_y_GatedParkSWFlt_Value: accessed-variable=VeTRGR_y_GatedParkSWFlt.Value
              OUT_VeTRGR_e_TransDirctnSt_Value: accessed-variable=VeTRGR_e_TransDirctnSt.Value
              OUT_VeTRGR_e_TransShiftLeverPstn_Value: accessed-variable=VeTRGR_e_TransShiftLeverPstn.Value
              OUT_VeTRGR_b_ShifterNotLocked_Value: accessed-variable=VeTRGR_b_ShifterNotLocked.Value
              OUT_VeTRGR_e_TXFault_Value: accessed-variable=VeTRGR_e_TXFault.Value
              OUT_VeTRGR_e_PRNDLBlink_Value: accessed-variable=VeTRGR_e_PRNDLBlink.Value
              OUT_VeTRGR_e_AutoPosCorrMdReq_Value: accessed-variable=VeTRGR_e_AutoPosCorrMdReq.Value
              OUT_VeTRGR_e_PRND_DebugSt_Value: accessed-variable=VeTRGR_e_PRND_DebugSt.Value
              OUT_VeTRGR_e_PPawlCmnd_Value: accessed-variable=VeTRGR_e_PPawlCmnd.Value
              OUT_VeTRGR_e_ArbPRNDReq_Value: accessed-variable=VeTRGR_e_ArbPRNDReq.Value
              OUT_VeTRGR_e_PRNDLReq_Value: accessed-variable=VeTRGR_e_PRNDLReq.Value
              OUT_VeTRGR_b_EngSt_Enbl_Rq_Value: accessed-variable=VeTRGR_b_EngSt_Enbl_Rq.Value
              OUT_VeTRGR_b_GatedParkSw_Value: accessed-variable=VeTRGR_b_GatedParkSw.Value
              OUT_VeTRGR_b_R_Shift_Block_Value: accessed-variable=VeTRGR_b_R_Shift_Block.Value
              OUT_VeTRGR_e_EPB_Hold_Req_Value: accessed-variable=VeTRGR_e_EPB_Hold_Req.Value
              OUT_VeTRGR_b_HCPReset_Value: accessed-variable=VeTRGR_b_HCPReset.Value
              OUT_VeTRGR_e_Gr_Value: accessed-variable=VeTRGR_e_Gr.Value
              OUT_VeTRGR_e_Gr_Target_Value: accessed-variable=VeTRGR_e_Gr_Target.Value
              OUT_VeTRGR_e_CurrentGear_Value: accessed-variable=VeTRGR_e_CurrentGear.Value
              OUT_VeTRGR_e_CurrentGrForDisp_Value: accessed-variable=VeTRGR_e_CurrentGrForDisp.Value
              OUT_VeTRGR_e_TargetGear_Value: accessed-variable=VeTRGR_e_TargetGear.Value
              OUT_VeTRGR_g_ClusterWarnings_Value: accessed-variable=VeTRGR_g_ClusterWarnings.Value
              OUT_VeTRGR_e_CANC_TransShiftPstn_Value: accessed-variable=VeTRGR_e_CANC_TransShiftPstn.Value
              OUT_VeTRGR_b_CANC_TransShiftPstnFA_Value: accessed-variable=VeTRGR_b_CANC_TransShiftPstnFA.Value
              OUT_VeTRGR_e_DPT_TransShiftPstn_Value: accessed-variable=VeTRGR_e_DPT_TransShiftPstn.Value
              OUT_VeTRGR_b_DPT_TransShiftPstnFA_Value: accessed-variable=VeTRGR_b_DPT_TransShiftPstnFA.Value
              OUT_VeTRGR_b_DisableDrvAllwd_Value: accessed-variable=VeTRGR_b_DisableDrvAllwd.Value
              OUT_VeTRGR_b_ParkWithSpd_Value: accessed-variable=VeTRGR_b_ParkWithSpd.Value
              OUT_VeTRGR_b_EPBApplyDisp_Value: accessed-variable=VeTRGR_b_EPBApplyDisp.Value
              OUT_VeTRGR_b_TxFaultSNA_Value: accessed-variable=VeTRGR_b_TxFaultSNA.Value
              OUT_VeTRGR_b_GearIndicationSts_Value: accessed-variable=VeTRGR_b_GearIndicationSts.Value
              OUT_VeTRGR_b_ParkingSts_Value: accessed-variable=VeTRGR_b_ParkingSts.Value
              OUT_VeTRGR_b_ParkingFailSts_Value: accessed-variable=VeTRGR_b_ParkingFailSts.Value
              OUT_VeTRGR_b_OvrdToParkLatch_Value: accessed-variable=VeTRGR_b_OvrdToParkLatch.Value
              OUT_VeTRGR_b_OvrdToNeutral_Value: accessed-variable=VeTRGR_b_OvrdToNeutral.Value
              OUT_VeTRGR_b_LatchShftrLockP_Value: accessed-variable=VeTRGR_b_LatchShftrLockP.Value
              OUT_VeTRGR_b_LatchShftrLockN_Value: accessed-variable=VeTRGR_b_LatchShftrLockN.Value
              OUT_VeTRGR_b_LatchShftrRBlock_Value: accessed-variable=VeTRGR_b_LatchShftrRBlock.Value
              OUT_VeTRGR_b_ShiftLockNCompleted_Value: accessed-variable=VeTRGR_b_ShiftLockNCompleted.Value
              OUT_VeTRGR_e_ReverseSts_Value: accessed-variable=VeTRGR_e_ReverseSts.Value
              OUT_VeTRGR_b_Secured_To_Shtdwn_Value: accessed-variable=VeTRGR_b_Secured_To_Shtdwn.Value
              OUT_VeTRGR_b_UnexpRst_Value: accessed-variable=VeTRGR_b_UnexpRst.Value
              OUT_VeTRGR_b_Reject_D_Value: accessed-variable=VeTRGR_b_Reject_D.Value
              OUT_VeTRGR_b_Reject_R_Value: accessed-variable=VeTRGR_b_Reject_R.Value
              OUT_VeTRGR_e_ESMTransRngSt_Value: accessed-variable=VeTRGR_e_ESMTransRngSt.Value
              OUT_VeTRGR_b_ShifterLocked_Value: accessed-variable=VeTRGR_b_ShifterLocked.Value
              OUT_VeTRGR_b_TransmissionFailSts_Value: accessed-variable=VeTRGR_b_TransmissionFailSts.Value
              OUT_VeTRGR_b_CrankEnabled_Value: accessed-variable=VeTRGR_b_CrankEnabled.Value
              OUT_VeTRGR_b_BrkApplied_Value: accessed-variable=VeTRGR_b_BrkApplied.Value
              OUT_VeTRGR_b_BrakeFA_Value: accessed-variable=VeTRGR_b_BrakeFA.Value
              OUT_VeTRGR_b_AutoPark_DAI_Value: accessed-variable=VeTRGR_b_AutoPark_DAI.Value
              OUT_VeTRGR_d_IP_PRNDLTestFlags_Value: accessed-variable=VeTRGR_d_IP_PRNDLTestFlags.Value, variation-point={short-label=vpOUT_VeTRGR_d_IP_PRNDLTestFlags_Value, sw-syscond=1}
              OUT_VeTRGR_y_PRNDLTestFailStatus_Value: accessed-variable=VeTRGR_y_PRNDLTestFailStatus.Value, variation-point={short-label=vpOUT_VeTRGR_y_PRNDLTestFailStatus_Value, sw-syscond=1}
              OUT_VeTRGR_b_ADAS_Allowed_Value: accessed-variable=VeTRGR_b_ADAS_Allowed.Value
              OUT_VeTRGR_b_ReadyToPark_Value: accessed-variable=VeTRGR_b_ReadyToPark.Value
              OUT_VeTRGR_b_TransDirctnStFA_Value: accessed-variable=VeTRGR_b_TransDirctnStFA.Value
              OUT_VeTRGR_e_TransShiftPstn_Value: accessed-variable=VeTRGR_e_TransShiftPstn.Value
              OUT_VeTRGR_b_Force_Park_Neutral_Value: accessed-variable=VeTRGR_b_Force_Park_Neutral.Value
              OUT_VeTRGR_e_HCP_Honored_Pstn_Value: accessed-variable=VeTRGR_e_HCP_Honored_Pstn.Value
              OUT_VeTRGR_e_ShftRngSt_AEMD_Value: accessed-variable=VeTRGR_e_ShftRngSt_AEMD.Value
              OUT_VeTRGR_e_Braking_Mode_Sts_Value: accessed-variable=VeTRGR_e_Braking_Mode_Sts.Value
              OUT_VeTRGR_e_Braking_Mode_Indication_Sts_Value: accessed-variable=VeTRGR_e_Braking_Mode_Indication_Sts.Value
              OUT_VeTRGR_e_SecureIdleSts_Value: accessed-variable=VeTRGR_e_SecureIdleSts.Value
              OUT_VeTRGR_e_SecureIdle_HMI_Value: accessed-variable=VeTRGR_e_SecureIdle_HMI.Value
        TRGR_MedTED
          data-receive-point-by-arguments:
            96 x access:
              IN_VeADAR_e_LeftActuationStatus_Value: accessed-variable=VeADAR_e_LeftActuationStatus.Value, variation-point={short-label=vpIN_VeADAR_e_LeftActuationStatus_Value, sw-syscond=1}
              IN_VeADAR_e_RightActuationStatus_Value: accessed-variable=VeADAR_e_RightActuationStatus.Value, variation-point={short-label=vpIN_VeADAR_e_RightActuationStatus_Value, sw-syscond=1}
              IN_VeADIR_b_LftWEDClosingFail_Value: accessed-variable=VeADIR_b_LftWEDClosingFail.Value, variation-point={short-label=vpIN_VeADIR_b_LftWEDClosingFail_Value, sw-syscond=1}
              IN_VeADIR_b_RtWEDClosingFail_Value: accessed-variable=VeADIR_b_RtWEDClosingFail.Value, variation-point={short-label=vpIN_VeADIR_b_RtWEDClosingFail_Value, sw-syscond=1}
              IN_VeADIR_e_WEDMechFailure_Sts_Value: accessed-variable=VeADIR_e_WEDMechFailure_Sts.Value, variation-point={short-label=vpIN_VeADIR_e_WEDMechFailure_Sts_Value, sw-syscond=1}
              IN_VeBRKR_P_BrkPrss_Value: accessed-variable=VeBRKR_P_BrkPrss.Value
              IN_VeBRKR_b_BrkPedalDscrtInptFA_Value: accessed-variable=VeBRKR_b_BrkPedalDscrtInptFA.Value
              IN_VeBRKR_b_BrkPrssFA_Value: accessed-variable=VeBRKR_b_BrkPrssFA.Value
              IN_VeBRKR_e_BrkPedalDscrtInpt_Value: accessed-variable=VeBRKR_e_BrkPedalDscrtInpt.Value
              IN_VeCCTR_b_CcAccelSts_Value: accessed-variable=VeCCTR_b_CcAccelSts.Value, variation-point={short-label=vpIN_VeCCTR_b_CcAccelSts_Value, sw-syscond=1}
              IN_VeCCTR_b_CcDecelSts_Value: accessed-variable=VeCCTR_b_CcDecelSts.Value, variation-point={short-label=vpIN_VeCCTR_b_CcDecelSts_Value, sw-syscond=1}
              IN_VeCSVR_b_VehSpdFA_Value: accessed-variable=VeCSVR_b_VehSpdFA.Value
              IN_VeCSVR_n_TransOutSpdSgndFltrd_Value: accessed-variable=VeCSVR_n_TransOutSpdSgndFltrd.Value
              IN_VeCSVR_v_VehSpdSigned_Value: accessed-variable=VeCSVR_v_VehSpdSigned.Value
              IN_VeDFIR_b_DsblDiagFailSafe_Value: accessed-variable=VeDFIR_b_DsblDiagFailSafe.Value, variation-point={short-label=vpIN_VeDFIR_b_DsblDiagFailSafe_Value, sw-syscond=1}
              IN_VeDFIR_b_PostCodeClrDiagDsbl_Value: accessed-variable=VeDFIR_b_PostCodeClrDiagDsbl.Value, variation-point={short-label=vpIN_VeDFIR_b_PostCodeClrDiagDsbl_Value, sw-syscond=1}
              IN_VeDMAB_y_StatusByte_LF_WHL_HubDisConActCntrl_Value: accessed-variable=VeDMAB_y_StatusByte_LF_WHL_HubDisConActCntrl.Value, variation-point={short-label=vpIN_VeDMAB_y_StatusByte_LF_WHL_HubDisConActCntrl_Value, sw-syscond=1}
              IN_VeDMAB_y_StatusByte_LF_WHL_HubDisConActPosSnsr_Value: accessed-variable=VeDMAB_y_StatusByte_LF_WHL_HubDisConActPosSnsr.Value, variation-point={short-label=vpIN_VeDMAB_y_StatusByte_LF_WHL_HubDisConActPosSnsr_Value, sw-syscond=1}
              IN_VeDMAB_y_StatusByte_LF_WHL_HubDisConActPosSnsrCktPerf_Value: accessed-variable=VeDMAB_y_StatusByte_LF_WHL_HubDisConActPosSnsrCktPerf.Value, variation-point={short-label=vpIN_VeDMAB_y_StatusByte_LF_WHL_HubDisConActPosSnsrCktPerf_Value, sw-syscond=1}
              IN_VeDMAB_y_StatusByte_ParkNeutSwOut_Value: accessed-variable=VeDMAB_y_StatusByte_ParkNeutSwOut.Value, variation-point={short-label=vpIN_VeDMAB_y_StatusByte_ParkNeutSwOut_Value, sw-syscond=1}
              IN_VeDMAB_y_StatusByte_RF_WHL_HubDisConActCntrl_Value: accessed-variable=VeDMAB_y_StatusByte_RF_WHL_HubDisConActCntrl.Value, variation-point={short-label=vpIN_VeDMAB_y_StatusByte_RF_WHL_HubDisConActCntrl_Value, sw-syscond=1}
              IN_VeDMAB_y_StatusByte_RF_WHL_HubDisConActPosSnsr_Value: accessed-variable=VeDMAB_y_StatusByte_RF_WHL_HubDisConActPosSnsr.Value, variation-point={short-label=vpIN_VeDMAB_y_StatusByte_RF_WHL_HubDisConActPosSnsr_Value, sw-syscond=1}
              IN_VeDMAB_y_StatusByte_RF_WHL_HubDisConActPosSnsrCktPerf_Value: accessed-variable=VeDMAB_y_StatusByte_RF_WHL_HubDisConActPosSnsrCktPerf.Value, variation-point={short-label=vpIN_VeDMAB_y_StatusByte_RF_WHL_HubDisConActPosSnsrCktPerf_Value, sw-syscond=1}
              IN_VeDMIR_e_BrakingMdReq_Value: accessed-variable=VeDMIR_e_BrakingMdReq.Value, variation-point={short-label=vpIN_VeDMIR_e_BrakingMdReq_Value, sw-syscond=1}
              IN_VeESSR_e_EngStartStopSt_Value: accessed-variable=VeESSR_e_EngStartStopSt.Value, variation-point={short-label=vpIN_VeESSR_e_EngStartStopSt_Value, sw-syscond=1}
              IN_VeFCPR_b_FCPS_H2_RefuelSts_Value: accessed-variable=VeFCPR_b_FCPS_H2_RefuelSts.Value, variation-point={short-label=vpIN_VeFCPR_b_FCPS_H2_RefuelSts_Value, sw-syscond=1}
              IN_VeFWDR_e_Tcase_Stat_Value: accessed-variable=VeFWDR_e_Tcase_Stat.Value, variation-point={short-label=vpIN_VeFWDR_e_Tcase_Stat_Value, sw-syscond=1}
              IN_VeGENR_U_IBS_BattVoltOut_Value: accessed-variable=VeGENR_U_IBS_BattVoltOut.Value, variation-point={short-label=vpIN_VeGENR_U_IBS_BattVoltOut_Value, sw-syscond=1}
              IN_VeHPMR_b_CntrlrPwrHold_Value: accessed-variable=VeHPMR_b_CntrlrPwrHold.Value, variation-point={short-label=vpIN_VeHPMR_b_CntrlrPwrHold_Value, sw-syscond=1}
              IN_VeHPMR_b_PropSysActv_Value: accessed-variable=VeHPMR_b_PropSysActv.Value, variation-point={short-label=vpIN_VeHPMR_b_PropSysActv_Value, sw-syscond=1}
              IN_VeHSWR_b_HoodOpen_Value: accessed-variable=VeHSWR_b_HoodOpen.Value, variation-point={short-label=vpIN_VeHSWR_b_HoodOpen_Value, sw-syscond=1}
              IN_VeINVR_e_MtrA_6SOEnbl_Value: accessed-variable=VeINVR_e_MtrA_6SOEnbl.Value, variation-point={short-label=vpIN_VeINVR_e_MtrA_6SOEnbl_Value, sw-syscond=1}
              IN_VeINVR_e_MtrA_InvrtrSt_Value: accessed-variable=VeINVR_e_MtrA_InvrtrSt.Value, variation-point={short-label=vpIN_VeINVR_e_MtrA_InvrtrSt_Value, sw-syscond=1}
              IN_VeINVR_e_MtrB_InvrtrSt_Value: accessed-variable=VeINVR_e_MtrB_InvrtrSt.Value, variation-point={short-label=vpIN_VeINVR_e_MtrB_InvrtrSt_Value, sw-syscond=1}
              IN_VeOBCR_b_ValidPluginDetected_Value: accessed-variable=VeOBCR_b_ValidPluginDetected.Value
              IN_VeOSMR_n_InputSpdMaxM1_Value: accessed-variable=VeOSMR_n_InputSpdMaxM1.Value, variation-point={short-label=vpIN_VeOSMR_n_InputSpdMaxM1_Value, sw-syscond=1}
              IN_VeOSMR_n_InputSpdMaxM2_Value: accessed-variable=VeOSMR_n_InputSpdMaxM2.Value, variation-point={short-label=vpIN_VeOSMR_n_InputSpdMaxM2_Value, sw-syscond=1}
              IN_VePLTR_b_DAI_Enbl_Value: accessed-variable=VePLTR_b_DAI_Enbl.Value, variation-point={short-label=vpIN_VePLTR_b_DAI_Enbl_Value, sw-syscond=1}
              IN_VePLTR_b_ERS_SWFA_Value: accessed-variable=VePLTR_b_ERS_SWFA.Value, variation-point={short-label=vpIN_VePLTR_b_ERS_SWFA_Value, sw-syscond=1}
              IN_VePLTR_b_ESSRqShftPark_Value: accessed-variable=VePLTR_b_ESSRqShftPark.Value, variation-point={short-label=vpIN_VePLTR_b_ESSRqShftPark_Value, sw-syscond=1}
              IN_VePLTR_b_FobSearchResult_FA_Value: accessed-variable=VePLTR_b_FobSearchResult_FA.Value, variation-point={short-label=vpIN_VePLTR_b_FobSearchResult_FA_Value, sw-syscond=1}
              IN_VePLTR_b_ImmoParkReq_Value: accessed-variable=VePLTR_b_ImmoParkReq.Value, variation-point={short-label=vpIN_VePLTR_b_ImmoParkReq_Value, sw-syscond=1}
              IN_VePLTR_b_InFieldMode_Value: accessed-variable=VePLTR_b_InFieldMode.Value, variation-point={short-label=vpIN_VePLTR_b_InFieldMode_Value, sw-syscond=1}
              IN_VePLTR_b_MRM_Status_FA_Value: accessed-variable=VePLTR_b_MRM_Status_FA.Value, variation-point={short-label=vpIN_VePLTR_b_MRM_Status_FA_Value, sw-syscond=1}
              IN_VePLTR_b_PRNDFailSts_Value: accessed-variable=VePLTR_b_PRNDFailSts.Value, variation-point={short-label=vpIN_VePLTR_b_PRNDFailSts_Value, sw-syscond=1}
              IN_VePLTR_b_ParkingGearShiftReq_BSM_FA_Value: accessed-variable=VePLTR_b_ParkingGearShiftReq_BSM_FA.Value, variation-point={short-label=vpIN_VePLTR_b_ParkingGearShiftReq_BSM_FA_Value, sw-syscond=1}
              IN_VePLTR_b_Prmry_TransShiftPstnFA_Value: accessed-variable=VePLTR_b_Prmry_TransShiftPstnFA.Value, variation-point={short-label=vpIN_VePLTR_b_Prmry_TransShiftPstnFA_Value, sw-syscond=1}
              IN_VePLTR_b_ProxiCADM_Value: accessed-variable=VePLTR_b_ProxiCADM.Value, variation-point={short-label=vpIN_VePLTR_b_ProxiCADM_Value, sw-syscond=1}
              IN_VePLTR_b_ProxiCADM2_Value: accessed-variable=VePLTR_b_ProxiCADM2.Value, variation-point={short-label=vpIN_VePLTR_b_ProxiCADM2_Value, sw-syscond=1}
              IN_VePLTR_b_RFHub_ForcePark_Value: accessed-variable=VePLTR_b_RFHub_ForcePark.Value, variation-point={short-label=vpIN_VePLTR_b_RFHub_ForcePark_Value, sw-syscond=1}
              IN_VePLTR_b_RackFaultFA_Value: accessed-variable=VePLTR_b_RackFaultFA.Value, variation-point={short-label=vpIN_VePLTR_b_RackFaultFA_Value, sw-syscond=1}
              IN_VePLTR_b_Scndry_TransShiftPstnFA_Value: accessed-variable=VePLTR_b_Scndry_TransShiftPstnFA.Value, variation-point={short-label=vpIN_VePLTR_b_Scndry_TransShiftPstnFA_Value, sw-syscond=1}
              IN_VePLTR_b_Secure_Idle_Req_Value: accessed-variable=VePLTR_b_Secure_Idle_Req.Value, variation-point={short-label=vpIN_VePLTR_b_Secure_Idle_Req_Value, sw-syscond=1}
              IN_VePLTR_b_Secure_Idle_Req_FA_Value: accessed-variable=VePLTR_b_Secure_Idle_Req_FA.Value, variation-point={short-label=vpIN_VePLTR_b_Secure_Idle_Req_FA_Value, sw-syscond=1}
              IN_VePLTR_b_SelectSpdSts_FA_Value: accessed-variable=VePLTR_b_SelectSpdSts_FA.Value, variation-point={short-label=vpIN_VePLTR_b_SelectSpdSts_FA_Value, sw-syscond=1}
              IN_VePLTR_b_ShftLckFlt_Value: accessed-variable=VePLTR_b_ShftLckFlt.Value, variation-point={short-label=vpIN_VePLTR_b_ShftLckFlt_Value, sw-syscond=1}
              IN_VePLTR_b_ShftSnsFA_Value: accessed-variable=VePLTR_b_ShftSnsFA.Value, variation-point={short-label=vpIN_VePLTR_b_ShftSnsFA_Value, sw-syscond=1}
              IN_VePLTR_b_ShiftDspFlt_Value: accessed-variable=VePLTR_b_ShiftDspFlt.Value, variation-point={short-label=vpIN_VePLTR_b_ShiftDspFlt_Value, sw-syscond=1}
              IN_VePLTR_b_ShiftLeverFailSts_Value: accessed-variable=VePLTR_b_ShiftLeverFailSts.Value, variation-point={short-label=vpIN_VePLTR_b_ShiftLeverFailSts_Value, sw-syscond=1}
              IN_VePLTR_e_AutoPosCorrMd_Value: accessed-variable=VePLTR_e_AutoPosCorrMd.Value, variation-point={short-label=vpIN_VePLTR_e_AutoPosCorrMd_Value, sw-syscond=1}
              IN_VePLTR_e_EPBHoldSts_Value: accessed-variable=VePLTR_e_EPBHoldSts.Value
              IN_VePLTR_e_ERS_SW_Value: accessed-variable=VePLTR_e_ERS_SW.Value, variation-point={short-label=vpIN_VePLTR_e_ERS_SW_Value, sw-syscond=1}
              IN_VePLTR_e_ESMTransRngSt_Value: accessed-variable=VePLTR_e_ESMTransRngSt.Value, variation-point={short-label=vpIN_VePLTR_e_ESMTransRngSt_Value, sw-syscond=1}
              IN_VePLTR_e_MRM_Status_Value: accessed-variable=VePLTR_e_MRM_Status.Value, variation-point={short-label=vpIN_VePLTR_e_MRM_Status_Value, sw-syscond=1}
              IN_VePLTR_e_MRM_Status_C2_Value: accessed-variable=VePLTR_e_MRM_Status_C2.Value, variation-point={short-label=vpIN_VePLTR_e_MRM_Status_C2_Value, sw-syscond=1}
              IN_VePLTR_e_MRM_Status_C2_FA_Value: accessed-variable=VePLTR_e_MRM_Status_C2_FA.Value, variation-point={short-label=vpIN_VePLTR_e_MRM_Status_C2_FA_Value, sw-syscond=1}
              IN_VePLTR_e_ParkingGearShiftReq_BSM_Value: accessed-variable=VePLTR_e_ParkingGearShiftReq_BSM.Value, variation-point={short-label=vpIN_VePLTR_e_ParkingGearShiftReq_BSM_Value, sw-syscond=1}
              IN_VePLTR_e_Prmry_TransShiftPstn_Value: accessed-variable=VePLTR_e_Prmry_TransShiftPstn.Value, variation-point={short-label=vpIN_VePLTR_e_Prmry_TransShiftPstn_Value, sw-syscond=1}
              IN_VePLTR_e_Scndry_TransShiftPstn_Value: accessed-variable=VePLTR_e_Scndry_TransShiftPstn.Value, variation-point={short-label=vpIN_VePLTR_e_Scndry_TransShiftPstn_Value, sw-syscond=1}
              IN_VePLTR_e_SelectSpdSts_Value: accessed-variable=VePLTR_e_SelectSpdSts.Value, variation-point={short-label=vpIN_VePLTR_e_SelectSpdSts_Value, sw-syscond=1}
              IN_VePLTR_e_ShiftLeverPosReq_Value: accessed-variable=VePLTR_e_ShiftLeverPosReq.Value, variation-point={short-label=vpIN_VePLTR_e_ShiftLeverPosReq_Value, sw-syscond=1}
              IN_VePLTR_e_TowHaulMode_Value: accessed-variable=VePLTR_e_TowHaulMode.Value, variation-point={short-label=vpIN_VePLTR_e_TowHaulMode_Value, sw-syscond=1}
              IN_VePLTR_e_VehicleCountryCode_Value: accessed-variable=VePLTR_e_VehicleCountryCode.Value, variation-point={short-label=vpIN_VePLTR_e_VehicleCountryCode_Value, sw-syscond=1}
              IN_VePLTR_phi_EstSlopeAngle_Value: accessed-variable=VePLTR_phi_EstSlopeAngle.Value, variation-point={short-label=vpIN_VePLTR_phi_EstSlopeAngle_Value, sw-syscond=1}
              IN_VePLTR_y_FobSearchResult_Value: accessed-variable=VePLTR_y_FobSearchResult.Value, variation-point={short-label=vpIN_VePLTR_y_FobSearchResult_Value, sw-syscond=1}
              IN_VePLTR_y_GatedParkSwFlt_Value: accessed-variable=VePLTR_y_GatedParkSwFlt.Value, variation-point={short-label=vpIN_VePLTR_y_GatedParkSwFlt_Value, sw-syscond=1}
              IN_VePMDR_b_EngineOffRequest_Value: accessed-variable=VePMDR_b_EngineOffRequest.Value, variation-point={short-label=vpIN_VePMDR_b_EngineOffRequest_Value, sw-syscond=1}
              IN_VePMDR_e_PMM_PowerMode_Value: accessed-variable=VePMDR_e_PMM_PowerMode.Value, variation-point={short-label=vpIN_VePMDR_e_PMM_PowerMode_Value, sw-syscond=1}
              IN_VePPCR_b_ApplyEPB_Value: accessed-variable=VePPCR_b_ApplyEPB.Value, variation-point={short-label=vpIN_VePPCR_b_ApplyEPB_Value, sw-syscond=1}
              IN_VePPCR_b_PPawlFlt_InhibitMtr_Value: accessed-variable=VePPCR_b_PPawlFlt_InhibitMtr.Value, variation-point={short-label=vpIN_VePPCR_b_PPawlFlt_InhibitMtr_Value, sw-syscond=1}
              IN_VePPCR_b_PPawlFlt_UnknownPos_Value: accessed-variable=VePPCR_b_PPawlFlt_UnknownPos.Value, variation-point={short-label=vpIN_VePPCR_b_PPawlFlt_UnknownPos_Value, sw-syscond=1}
              IN_VePPCR_b_PPawl_CurrSnsrFlt_Value: accessed-variable=VePPCR_b_PPawl_CurrSnsrFlt.Value, variation-point={short-label=vpIN_VePPCR_b_PPawl_CurrSnsrFlt_Value, sw-syscond=1}
              IN_VePPCR_b_PPawl_PosSnsrFlt_Value: accessed-variable=VePPCR_b_PPawl_PosSnsrFlt.Value, variation-point={short-label=vpIN_VePPCR_b_PPawl_PosSnsrFlt_Value, sw-syscond=1}
              IN_VePPCR_b_PPawl_TXFlt_Value: accessed-variable=VePPCR_b_PPawl_TXFlt.Value, variation-point={short-label=vpIN_VePPCR_b_PPawl_TXFlt_Value, sw-syscond=1}
              IN_VePPCR_e_PPawlFdbck_Value: accessed-variable=VePPCR_e_PPawlFdbck.Value, variation-point={short-label=vpIN_VePPCR_e_PPawlFdbck_Value, sw-syscond=1}
              IN_VePPCR_e_PPawlRequest_Value: accessed-variable=VePPCR_e_PPawlRequest.Value, variation-point={short-label=vpIN_VePPCR_e_PPawlRequest_Value, sw-syscond=1}
              IN_VeRTMR_e_WEDLearningProcedure_Value: accessed-variable=VeRTMR_e_WEDLearningProcedure.Value, variation-point={short-label=vpIN_VeRTMR_e_WEDLearningProcedure_Value, sw-syscond=1}
              IN_VeSRAR_b_DrvAllwd_Value: accessed-variable=VeSRAR_b_DrvAllwd.Value
              IN_VeSRAR_b_NeutAllwd_Value: accessed-variable=VeSRAR_b_NeutAllwd.Value
              IN_VeSSDR_b_DrvAllwd_Value: accessed-variable=VeSSDR_b_DrvAllwd.Value
              IN_VeSSDR_b_DrvAllwdTPChck_Value: accessed-variable=VeSSDR_b_DrvAllwdTPChck.Value, variation-point={short-label=vpIN_VeSSDR_b_DrvAllwdTPChck_Value, sw-syscond=1}
              IN_VeSSDR_b_NeutAllwd_Value: accessed-variable=VeSSDR_b_NeutAllwd.Value
              IN_VeTISR_n_InputSpeed_Value: accessed-variable=VeTISR_n_InputSpeed.Value, variation-point={short-label=vpIN_VeTISR_n_InputSpeed_Value, sw-syscond=1}
              IN_VeTRIR_b_SCCActv_Value: accessed-variable=VeTRIR_b_SCCActv.Value, variation-point={short-label=vpIN_VeTRIR_b_SCCActv_Value, sw-syscond=1}
              IN_VeVSDR_b_PrimNoFA_Value: accessed-variable=VeVSDR_b_PrimNoFA.Value
              IN_VeVTLR_e_DschrgSysSts_Value: accessed-variable=VeVTLR_e_DschrgSysSts.Value, variation-point={short-label=vpIN_VeVTLR_e_DschrgSysSts_Value, sw-syscond=1}
          data-send-points:
            68 x access:
              OUT_VeTRGR_y_GatedParkSWFlt_Value: accessed-variable=VeTRGR_y_GatedParkSWFlt.Value
              OUT_VeTRGR_e_TransDirctnSt_Value: accessed-variable=VeTRGR_e_TransDirctnSt.Value
              OUT_VeTRGR_e_TransShiftLeverPstn_Value: accessed-variable=VeTRGR_e_TransShiftLeverPstn.Value
              OUT_VeTRGR_e_CANC_TransShiftPstn_Value: accessed-variable=VeTRGR_e_CANC_TransShiftPstn.Value
              OUT_VeTRGR_b_CANC_TransShiftPstnFA_Value: accessed-variable=VeTRGR_b_CANC_TransShiftPstnFA.Value
              OUT_VeTRGR_e_DPT_TransShiftPstn_Value: accessed-variable=VeTRGR_e_DPT_TransShiftPstn.Value
              OUT_VeTRGR_b_DPT_TransShiftPstnFA_Value: accessed-variable=VeTRGR_b_DPT_TransShiftPstnFA.Value
              OUT_VeTRGR_b_TransmissionFailSts_Value: accessed-variable=VeTRGR_b_TransmissionFailSts.Value
              OUT_VeTRGR_b_BrkApplied_Value: accessed-variable=VeTRGR_b_BrkApplied.Value
              OUT_VeTRGR_b_BrakeFA_Value: accessed-variable=VeTRGR_b_BrakeFA.Value
              OUT_VeTRGR_e_VldtdTransShiftRngSt_Value: accessed-variable=VeTRGR_e_VldtdTransShiftRngSt.Value
              OUT_VeTRGR_e_VldtdTransShiftDisp_Value: accessed-variable=VeTRGR_e_VldtdTransShiftDisp.Value
              OUT_VaTRGR_b_AllowedModesGearsERS_Value: accessed-variable=VaTRGR_b_AllowedModesGearsERS.Value
              OUT_VeTRGR_e_TXFault_Value: accessed-variable=VeTRGR_e_TXFault.Value
              OUT_VeTRGR_e_PRNDLBlink_Value: accessed-variable=VeTRGR_e_PRNDLBlink.Value
              OUT_VeTRGR_e_AutoPosCorrMdReq_Value: accessed-variable=VeTRGR_e_AutoPosCorrMdReq.Value
              OUT_VeTRGR_e_PRND_DebugSt_Value: accessed-variable=VeTRGR_e_PRND_DebugSt.Value
              OUT_VeTRGR_e_PPawlCmnd_Value: accessed-variable=VeTRGR_e_PPawlCmnd.Value
              OUT_VeTRGR_e_ArbPRNDReq_Value: accessed-variable=VeTRGR_e_ArbPRNDReq.Value
              OUT_VeTRGR_b_EngSt_Enbl_Rq_Value: accessed-variable=VeTRGR_b_EngSt_Enbl_Rq.Value
              OUT_VeTRGR_b_GatedParkSw_Value: accessed-variable=VeTRGR_b_GatedParkSw.Value
              OUT_VeTRGR_b_R_Shift_Block_Value: accessed-variable=VeTRGR_b_R_Shift_Block.Value
              OUT_VeTRGR_e_EPB_Hold_Req_Value: accessed-variable=VeTRGR_e_EPB_Hold_Req.Value
              OUT_VeTRGR_b_HCPReset_Value: accessed-variable=VeTRGR_b_HCPReset.Value
              OUT_VeTRGR_b_DisableDrvAllwd_Value: accessed-variable=VeTRGR_b_DisableDrvAllwd.Value
              OUT_VeTRGR_b_ParkWithSpd_Value: accessed-variable=VeTRGR_b_ParkWithSpd.Value
              OUT_VeTRGR_b_EPBApplyDisp_Value: accessed-variable=VeTRGR_b_EPBApplyDisp.Value
              OUT_VeTRGR_b_TxFaultSNA_Value: accessed-variable=VeTRGR_b_TxFaultSNA.Value
              OUT_VeTRGR_b_GearIndicationSts_Value: accessed-variable=VeTRGR_b_GearIndicationSts.Value
              OUT_VeTRGR_b_ParkingSts_Value: accessed-variable=VeTRGR_b_ParkingSts.Value
              OUT_VeTRGR_b_ParkingFailSts_Value: accessed-variable=VeTRGR_b_ParkingFailSts.Value
              OUT_VeTRGR_b_OvrdToParkLatch_Value: accessed-variable=VeTRGR_b_OvrdToParkLatch.Value
              OUT_VeTRGR_b_OvrdToNeutral_Value: accessed-variable=VeTRGR_b_OvrdToNeutral.Value
              OUT_VeTRGR_b_LatchShftrLockP_Value: accessed-variable=VeTRGR_b_LatchShftrLockP.Value
              OUT_VeTRGR_b_LatchShftrLockN_Value: accessed-variable=VeTRGR_b_LatchShftrLockN.Value
              OUT_VeTRGR_b_LatchShftrRBlock_Value: accessed-variable=VeTRGR_b_LatchShftrRBlock.Value
              OUT_VeTRGR_b_ShiftLockNCompleted_Value: accessed-variable=VeTRGR_b_ShiftLockNCompleted.Value
              OUT_VeTRGR_e_ReverseSts_Value: accessed-variable=VeTRGR_e_ReverseSts.Value
              OUT_VeTRGR_b_Secured_To_Shtdwn_Value: accessed-variable=VeTRGR_b_Secured_To_Shtdwn.Value
              OUT_VeTRGR_b_UnexpRst_Value: accessed-variable=VeTRGR_b_UnexpRst.Value
              OUT_VeTRGR_b_Reject_D_Value: accessed-variable=VeTRGR_b_Reject_D.Value
              OUT_VeTRGR_b_Reject_R_Value: accessed-variable=VeTRGR_b_Reject_R.Value
              OUT_VeTRGR_e_ESMTransRngSt_Value: accessed-variable=VeTRGR_e_ESMTransRngSt.Value
              OUT_VeTRGR_b_CrankEnabled_Value: accessed-variable=VeTRGR_b_CrankEnabled.Value
              OUT_VeTRGR_b_AutoPark_DAI_Value: accessed-variable=VeTRGR_b_AutoPark_DAI.Value
              OUT_VeTRGR_b_ShifterNotLocked_Value: accessed-variable=VeTRGR_b_ShifterNotLocked.Value
              OUT_VeTRGR_e_PRNDLReq_Value: accessed-variable=VeTRGR_e_PRNDLReq.Value
              OUT_VeTRGR_e_Gr_Value: accessed-variable=VeTRGR_e_Gr.Value
              OUT_VeTRGR_e_Gr_Target_Value: accessed-variable=VeTRGR_e_Gr_Target.Value
              OUT_VeTRGR_e_CurrentGear_Value: accessed-variable=VeTRGR_e_CurrentGear.Value
              OUT_VeTRGR_e_CurrentGrForDisp_Value: accessed-variable=VeTRGR_e_CurrentGrForDisp.Value
              OUT_VeTRGR_e_TargetGear_Value: accessed-variable=VeTRGR_e_TargetGear.Value
              OUT_VeTRGR_b_ShifterLocked_Value: accessed-variable=VeTRGR_b_ShifterLocked.Value
              OUT_VeTRGR_e_VldtdTransRngSt_Value: accessed-variable=VeTRGR_e_VldtdTransRngSt.Value
              OUT_VeTRGR_g_ClusterWarnings_Value: accessed-variable=VeTRGR_g_ClusterWarnings.Value
              OUT_VeTRGR_d_IP_PRNDLTestFlags_Value: accessed-variable=VeTRGR_d_IP_PRNDLTestFlags.Value, variation-point={short-label=vpOUT_VeTRGR_d_IP_PRNDLTestFlags_Value, sw-syscond=1}
              OUT_VeTRGR_y_PRNDLTestFailStatus_Value: accessed-variable=VeTRGR_y_PRNDLTestFailStatus.Value, variation-point={short-label=vpOUT_VeTRGR_y_PRNDLTestFailStatus_Value, sw-syscond=1}
              OUT_AeTRGR_y_PwrDwnSts_AeTRGR_y_PwrDwnSts: accessed-variable=AeTRGR_y_PwrDwnSts.AeTRGR_y_PwrDwnSts, variation-point={short-label=vpOUT_AeTRGR_y_PwrDwnSts_AeTRGR_y_PwrDwnSts, sw-syscond=1}
              OUT_VeTRGR_b_ADAS_Allowed_Value: accessed-variable=VeTRGR_b_ADAS_Allowed.Value
              OUT_VeTRGR_b_ReadyToPark_Value: accessed-variable=VeTRGR_b_ReadyToPark.Value
              OUT_VeTRGR_b_TransDirctnStFA_Value: accessed-variable=VeTRGR_b_TransDirctnStFA.Value
              OUT_VeTRGR_b_Force_Park_Neutral_Value: accessed-variable=VeTRGR_b_Force_Park_Neutral.Value
              OUT_VeTRGR_e_HCP_Honored_Pstn_Value: accessed-variable=VeTRGR_e_HCP_Honored_Pstn.Value
              OUT_VeTRGR_e_ShftRngSt_AEMD_Value: accessed-variable=VeTRGR_e_ShftRngSt_AEMD.Value
              OUT_VeTRGR_b_ManualMode_Value: accessed-variable=VeTRGR_b_ManualMode.Value
              OUT_VeTRGR_e_TransShiftPstn_Value: accessed-variable=VeTRGR_e_TransShiftPstn.Value
              OUT_VeTRGR_e_Braking_Mode_Sts_Value: accessed-variable=VeTRGR_e_Braking_Mode_Sts.Value
              OUT_VeTRGR_e_Braking_Mode_Indication_Sts_Value: accessed-variable=VeTRGR_e_Braking_Mode_Indication_Sts.Value
        TRGR_PwrOff: variation-point={short-label=vpTRGR_PwrOff, sw-syscond=1}
          data-send-points:
            access OUT_BeTRGR_d_IP_PRNDLTestFlags_BeTRGR_d_IP_PRNDLTestFlags: accessed-variable=BeTRGR_d_IP_PRNDLTestFlags.BeTRGR_d_IP_PRNDLTestFlags, variation-point={short-label=vpOUT_BeTRGR_d_IP_PRNDLTestFlags_BeTRGR_d_IP_PRNDLTestFlags, sw-syscond=1}
            access OUT_NeTRGR_y_IP_PRNDLTestFailStatus_NeTRGR_y_IP_PRNDLTestFailStatus: accessed-variable=NeTRGR_y_IP_PRNDLTestFailStatus.NeTRGR_y_IP_PRNDLTestFailStatus, variation-point={short-label=vpOUT_NeTRGR_y_IP_PRNDLTestFailStatus_NeTRGR_y_IP_PRNDLTestFailStatus, sw-syscond=1}
        DIDWrite_RWD2800_IPEEPRNDLTstFlg
          data-receive-point-by-arguments:
            access IN_VeDCAB_d_IP_PRNDLTestFlags_DidWrite_Value: accessed-variable=VeDCAB_d_IP_PRNDLTestFlags_DidWrite.Value
      variation point proxy Variant_TRGR_CADM_Autopark: category=CONDITION, condition-access=1
      variation point proxy Variant_TRGR_FUNC_Enab: category=CONDITION, condition-access=1
